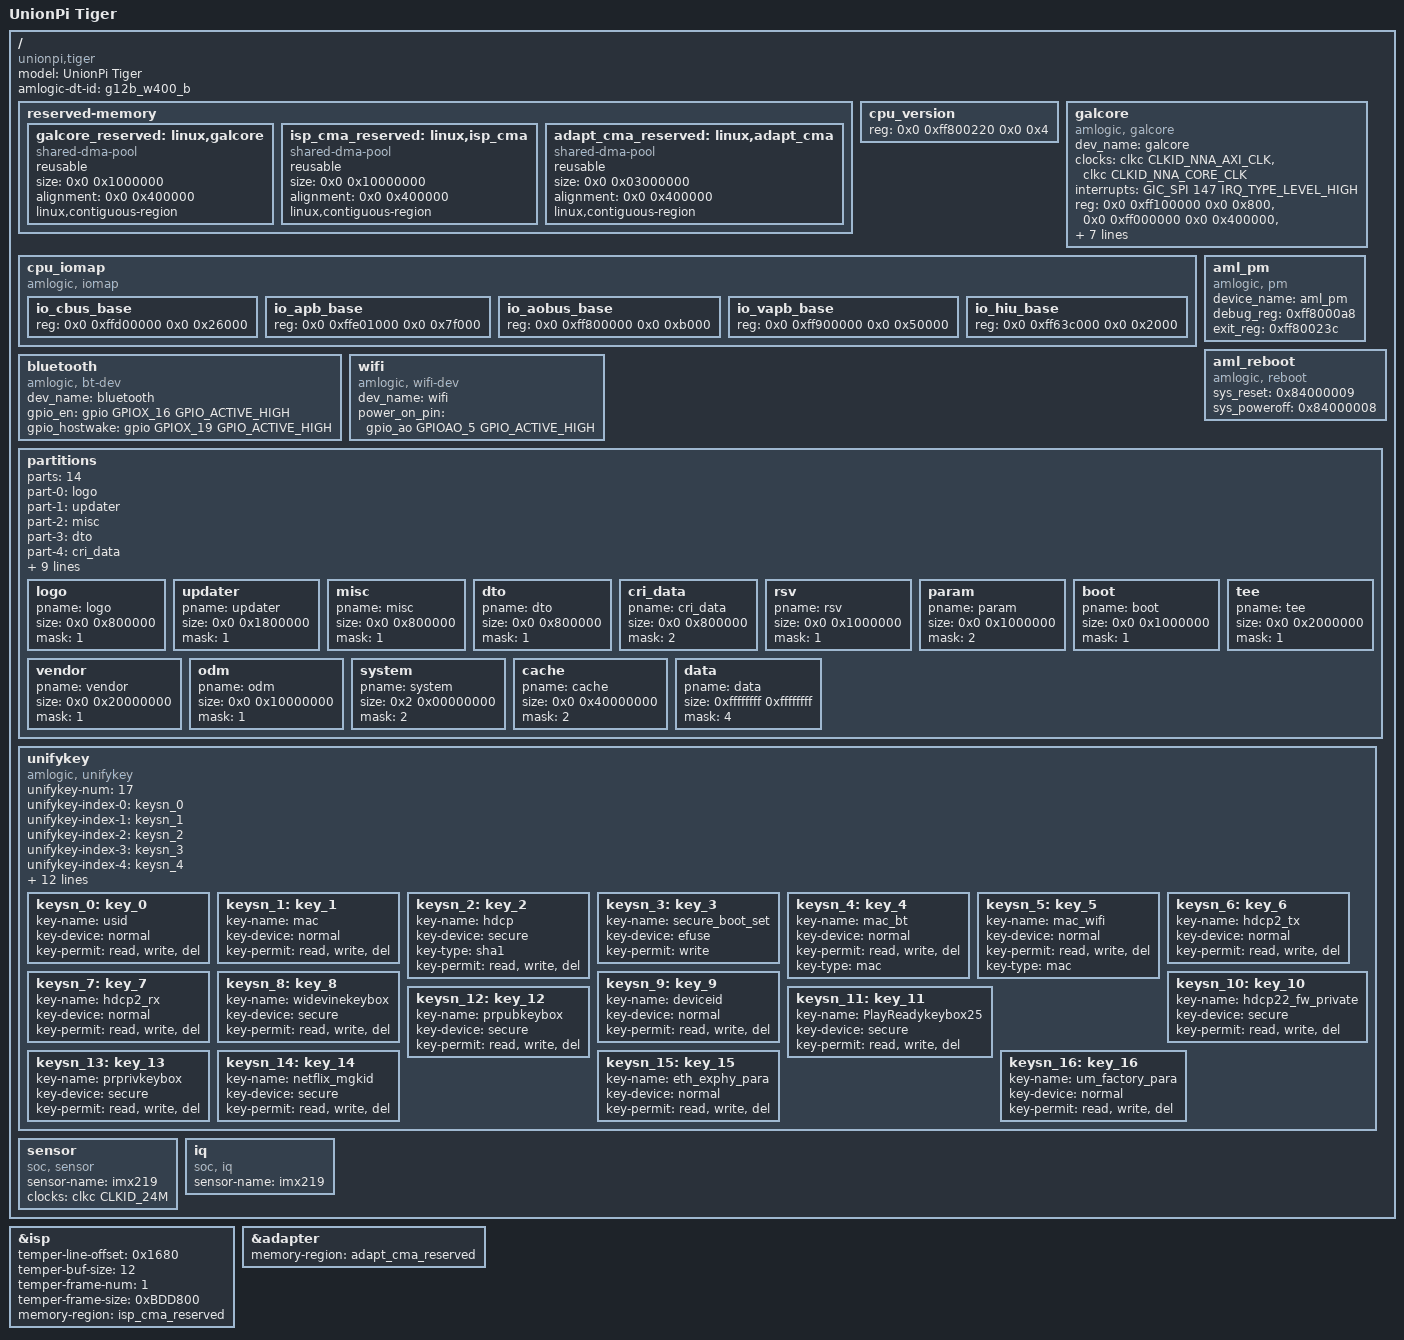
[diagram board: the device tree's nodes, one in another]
// SPDX-License-Identifier: (GPL-2.0+ OR MIT)
/*
 * Copyright (c) 2022 Unionman Technology Co., Ltd.
 * Copyright (c) 2019 BayLibre, SAS
 * Author: Neil Armstrong <narmstrong@baylibre.com>
 * Copyright (c) 2019 Christian Hewitt <christianshewitt@gmail.com>
 */

/dts-v1/;

#include "meson-g12b-a311d.dtsi"
#include "meson-unionpi-tiger.dtsi"
#include "meson-g12b-unionpi-tiger.dtsi"
#include "meson-g12b-media-legacy.dtsi"

/ {
	model = "UnionPi Tiger";
	compatible = "unionpi,tiger", "amlogic,a311d", "amlogic,g12b";
	amlogic-dt-id = "g12b_w400_b";

	reserved-memory {
		galcore_reserved:linux,galcore {
			compatible = "shared-dma-pool";
			reusable;
			size = <0x0 0x1000000>;
			alignment = <0x0 0x400000>;
			linux,contiguous-region;
		};
		
		isp_cma_reserved:linux,isp_cma {
			compatible = "shared-dma-pool";
			reusable;
			size = <0x0 0x10000000>;
			alignment = <0x0 0x400000>;
			linux,contiguous-region;
		};

		adapt_cma_reserved:linux,adapt_cma {
			compatible = "shared-dma-pool";
			reusable;
			size = <0x0 0x03000000>;
			alignment = <0x0 0x400000>;
			linux,contiguous-region;
		};
	};

	cpu_version {
		reg=<0x0 0xff800220 0x0 0x4>;
	};

	galcore {
		compatible = "amlogic, galcore";
		dev_name = "galcore";
		status = "okay";
		clocks = <&clkc CLKID_NNA_AXI_CLK>,
				<&clkc CLKID_NNA_CORE_CLK>;
		clock-names = "cts_vipnanoq_axi_clk_composite",
						"cts_vipnanoq_core_clk_composite";
		interrupts = <GIC_SPI 147 IRQ_TYPE_LEVEL_HIGH>;
		interrupt-names = "galcore";
		reg = <0x0 0xff100000 0x0 0x800>,
				<0x0 0xff000000 0x0 0x400000>,
				<0x0 0xff63c10c 0x0 0x4>,
				<0x0 0xff63c110 0x0 0x4>,
				<0x0 0xffd01088 0x0 0x4>,
				<0X0 0xff63c1c8 0X0 0x4>;
		reg-names = "NN_REG","NN_SRAM","NN_MEM0",
					"NN_MEM1","NN_RESET","NN_CLK";
		nn_power_version = <2>;
		nn_efuse = <0xff63003c 0x20>;

		memory-region = <&galcore_reserved>;
	};

	cpu_iomap {
		compatible = "amlogic, iomap";
		#address-cells=<2>;
		#size-cells=<2>;
		ranges;
		io_cbus_base {
			reg = <0x0 0xffd00000 0x0 0x26000>;
		};
		io_apb_base {
			reg = <0x0 0xffe01000 0x0 0x7f000>;
		};
		io_aobus_base {
			reg = <0x0 0xff800000 0x0 0xb000>;
		};
		io_vapb_base {
			reg = <0x0 0xff900000 0x0 0x50000>;
		};
		io_hiu_base {
			reg = <0x0 0xff63c000 0x0 0x2000>;
		};
	};

	aml_pm {
		compatible = "amlogic, pm";
		status = "okay";
		device_name = "aml_pm";
		debug_reg = <0xff8000a8>;
		exit_reg = <0xff80023c>;
	};

	aml_reboot{
		compatible = "amlogic, reboot";
		sys_reset = <0x84000009>;
		sys_poweroff = <0x84000008>;
	};

	bluetooth{
		compatible = "amlogic, bt-dev";
		dev_name = "bluetooth";
		status = "okay";
		gpio_en = <&gpio GPIOX_16 GPIO_ACTIVE_HIGH>;
		gpio_hostwake = <&gpio GPIOX_19 GPIO_ACTIVE_HIGH>;
	};

	wifi{
		compatible = "amlogic, wifi-dev";
		dev_name = "wifi";
		status = "okay";
		power_on_pin = <&gpio_ao GPIOAO_5 GPIO_ACTIVE_HIGH>;
	};

	partitions: partitions{
		parts = <14>;
		part-0 = <&logo>;
		part-1 = <&updater>;
		part-2 = <&misc>;
		part-3 = <&dto>;
		part-4 = <&cri_data>;
		part-5 = <&param>;
		part-6 = <&boot>;
		part-7 = <&rsv>;
		part-8 = <&tee>;
		part-9 = <&vendor>;
		part-10 = <&odm>;
		part-11 = <&system>;
		part-12 = <&cache>;
		part-13 = <&data>;

		logo:logo{
			pname = "logo";
			size = <0x0 0x800000>;
			mask = <1>;
		};

		updater:updater{
			pname = "updater";
			size = <0x0 0x1800000>;
			mask = <1>;
		};

		misc:misc{
			pname = "misc";
			size = <0x0 0x800000>;
			mask = <1>;
		};

		dto:dto{
			pname = "dto";
			size = <0x0 0x800000>;
			mask = <1>;
		};

		cri_data:cri_data{
			pname = "cri_data";
			size = <0x0 0x800000>;
			mask = <2>;
		};

		rsv:rsv{
			pname = "rsv";
			size = <0x0 0x1000000>;
			mask = <1>;
		};

		param:param{
			pname = "param";
			size = <0x0 0x1000000>;
			mask = <2>;
		};

		boot:boot{
			pname = "boot";
			size = <0x0 0x1000000>;
			mask = <1>;
		};

		tee:tee{
			pname = "tee";
			size = <0x0 0x2000000>;
			mask = <1>;
		};

		vendor:vendor{
			pname = "vendor";
			size = <0x0 0x20000000>;
			mask = <1>;
		};

		odm:odm{
			pname = "odm";
			size = <0x0 0x10000000>;
			mask = <1>;
		};

		system:system{
			pname = "system";
			size = <0x2 0x00000000>;
			mask = <2>;
		};

		cache:cache{
			pname = "cache";
			size = <0x0 0x40000000>;
			mask = <2>;
		};

		data:data{
			pname = "data";
			size = <0xffffffff 0xffffffff>;
			mask = <4>;
		};
	};

	unifykey{
		compatible = "amlogic, unifykey";
		status = "ok";
		unifykey-num = <17>;
		unifykey-index-0 = <&keysn_0>;
		unifykey-index-1 = <&keysn_1>;
		unifykey-index-2 = <&keysn_2>;
		unifykey-index-3 = <&keysn_3>;
		unifykey-index-4 = <&keysn_4>;
		unifykey-index-5 = <&keysn_5>;
		unifykey-index-6 = <&keysn_6>;
		unifykey-index-7 = <&keysn_7>;
		unifykey-index-8 = <&keysn_8>;
		unifykey-index-9 = <&keysn_9>;
		unifykey-index-10= <&keysn_10>;
		unifykey-index-11= <&keysn_11>;
		unifykey-index-12= <&keysn_12>;
		unifykey-index-13= <&keysn_13>;
		unifykey-index-14= <&keysn_14>;
		unifykey-index-15= <&keysn_15>;
		unifykey-index-16= <&keysn_16>;

		keysn_0: key_0{
			key-name = "usid";
			key-device = "normal";
			key-permit = "read","write","del";
		};
		keysn_1:key_1{
			key-name = "mac";
			key-device = "normal";
			key-permit = "read","write","del";
		};
		keysn_2:key_2{
			key-name = "hdcp";
			key-device = "secure";
			key-type = "sha1";
			key-permit = "read","write","del";
		};
		keysn_3:key_3{
			key-name = "secure_boot_set";
			key-device = "efuse";
			key-permit = "write";
		};
		keysn_4:key_4{
			key-name = "mac_bt";
			key-device = "normal";
			key-permit = "read","write","del";
			key-type	= "mac";
		};
		keysn_5:key_5{
			key-name = "mac_wifi";
			key-device = "normal";
			key-permit = "read","write","del";
			key-type = "mac";
		};
		keysn_6:key_6{
			key-name = "hdcp2_tx";
			key-device = "normal";
			key-permit = "read","write","del";
		};
		keysn_7:key_7{
			key-name = "hdcp2_rx";
			key-device = "normal";
			key-permit = "read","write","del";
		};
		keysn_8:key_8{
			key-name = "widevinekeybox";
			key-device = "secure";
			key-permit = "read","write","del";
		};
		keysn_9:key_9{
			key-name = "deviceid";
			key-device = "normal";
			key-permit = "read","write","del";
		};
		keysn_10:key_10{
			key-name = "hdcp22_fw_private";
			key-device = "secure";
			key-permit = "read","write","del";
		};
		keysn_11:key_11{
			key-name = "PlayReadykeybox25";
			key-device = "secure";
			key-permit = "read","write","del";
		};
		keysn_12:key_12{
			key-name = "prpubkeybox";// PlayReady
			key-device = "secure";
			key-permit = "read","write","del";
		};
		keysn_13:key_13{
			key-name = "prprivkeybox";// PlayReady
			key-device = "secure";
			key-permit = "read","write","del";
		};
		keysn_14:key_14{
			key-name = "netflix_mgkid";
			key-device = "secure";
			key-permit = "read","write","del";
		};
		keysn_15:key_15{
				key-name = "eth_exphy_para";
				key-device = "normal";
				key-permit = "read","write","del";
		};
		keysn_16:key_16{
			key-name = "um_factory_para";
			key-device = "normal";
			key-permit = "read","write","del";
		};
	};//End unifykey

	sensor: sensor {
			compatible = "soc, sensor";
			status = "okay";
			sensor-name = "imx219";
			pinctrl-names="default";
			clocks = <&clkc CLKID_24M>;
			clock-names = "g12a_24m";
	};

	iq: iq {
			compatible = "soc, iq";
			status = "okay";
			sensor-name = "imx219";
	};
};

&isp {
	status = "okay";
	temper-line-offset = <0x1680>;
	temper-buf-size = <12>;
	temper-frame-num = <1>;
	temper-frame-size = <0xBDD800>;
	memory-region = <&isp_cma_reserved>;
};

&adapter {
	status = "okay";
	memory-region = <&adapt_cma_reserved>;
};
